VERSION ""

NS_ :

BS_:

BU_: Turbocharger OnBoardDataLogger OffBoardDiagnosticTool2 OffBoardDiagnosticTool1 FileServer ParkingBrakeController SeatControl2 FanDriveController SteeringColumnUnit CommunicationUnitRadio CommunicationUnitSatellite CommunicationUnitCellular PropulsionBatteryCharger ChassisController2 ChassisController1 EngineValveControl AuxiliaryHeater2 AuxiliaryHeater1 ClutchUnit RampControl InformationSystem1 SuspensionSystemController2 OilSensor VehicleDynamicStability ExhaustEmissionController TransmissionDisplay2 TransmissionDisplay1 ClimateControl2 WaterPumpController RearAxleSteeringController LightingOperatorControl SeatController1 IgnitionController2 IgnitionController1 TirePressureController CabController2 CabController1 PneumaticSystemController SuspensionSystemController1 HydraulicPumpController EnduranceBrakingSystem RetarderExhaustEngine2 OnBoardDiagnosticUnit HeadwayController RetarderExhaustEngine1 CabDisplay1 ManagementComputer VirtualTerminal OffVehicleGateway PowerTakeOffFront HitchControl AuxiliaryValveControl BodyController TractorTrailerBridge1 StarterSystem ElectricalSystem VehicleSecurity VehicleNavigation AerodynamicControl ElectricalChargingSystem ClimateControl1 TripRecorder InstrumentCluster SuspensionDriveAxle2 SuspensionDriveAxle1 SuspensionSteerAxle SteeringController FuelSystem CruiseControl RetarderDriveline RetarderEngine BrakesDriveAxle2 BrakesDriveAxle1 BrakesSystemController BrakesSteerAxle AxleDrive2 AxleDrive1 AxleSteering PowerTakeOff ShiftConsoleSecondary ShiftConsolePrimary Transmission2 Transmission1 Engine2 Engine1

BO_ 2566842366 VH: 8 Vector__XXX
 SG_ TotalPowerTakeoffHours : 32|32@1+ (0.05,0) [0|210554060.75] "hr" Vector__XXX
 SG_ TotalVehicleHours : 0|32@1+ (0.05,0) [0|210554060.75] "hr" Vector__XXX

BO_ 2566839550 IO: 8 Vector__XXX
 SG_ EngTotalIdleHours : 32|32@1+ (0.05,0) [0|210554060.75] "hr" Vector__XXX
 SG_ EngTotalIdleFuelUsed : 0|32@1+ (0.5,0) [0|2105540607.5] "L" Vector__XXX

BO_ 2566848510 WFI: 8 Vector__XXX
 SG_ WaterInFuelIndicator : 0|2@1+ (1,0) [0|3] "" Vector__XXX

BO_ 2566841854 HOURS: 8 Vector__XXX
 SG_ EngTotalRevolutions : 32|32@1+ (1000,0) [0|4211081215000] "r" Vector__XXX
 SG_ EngTotalHoursOfOperation : 0|32@1+ (0.05,0) [0|210554060.75] "hr" Vector__XXX

BO_ 2566842878 LFC: 8 Vector__XXX
 SG_ EngTotalFuelUsed : 32|32@1+ (0.5,0) [0|2105540607.5] "L" Vector__XXX
 SG_ EngTripFuel : 0|32@1+ (0.5,0) [0|2105540607.5] "L" Vector__XXX

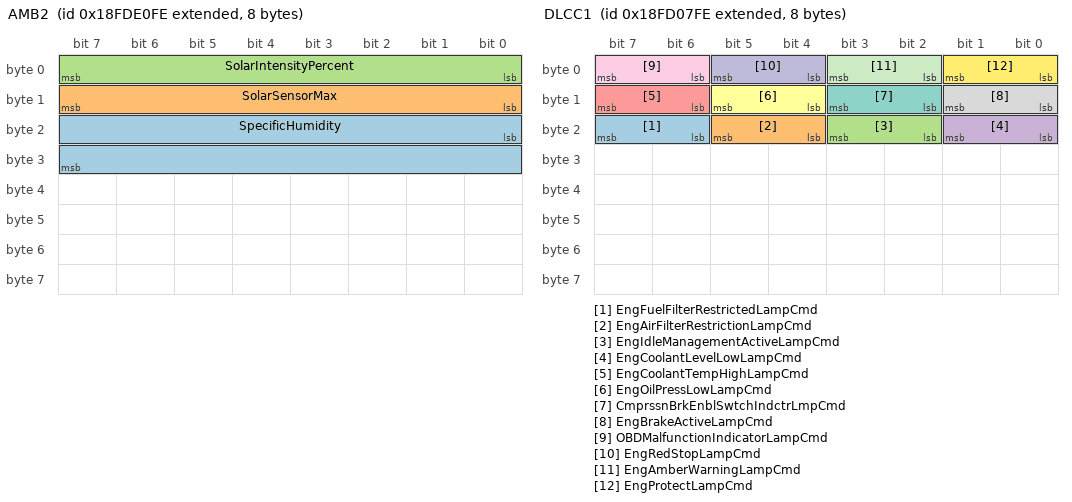
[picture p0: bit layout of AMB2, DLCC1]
BO_ 2566775038 AMB2: 8 Vector__XXX
 SG_ SpecificHumidity : 16|16@1+ (0.01,0) [0|642.55] "g/kg" Vector__XXX
 SG_ SolarSensorMax : 8|8@1+ (0.4,0) [0|100] "mW/cm/cm" Vector__XXX
 SG_ SolarIntensityPercent : 0|8@1+ (0.4,0) [0|100] "%" Vector__XXX

BO_ 2566834942 DM1: 22 Vector__XXX
 SG_ FlashRedStopLamp : 12|2@1+ (1,0) [0|3] "" Vector__XXX
 SG_ FlashProtectLamp : 8|2@1+ (1,0) [0|3] "" Vector__XXX
 SG_ FlashMalfuncIndicatorLamp : 14|2@1+ (1,0) [0|3] "" Vector__XXX
 SG_ FlashAmberWarningLamp : 10|2@1+ (1,0) [0|3] "" Vector__XXX
 SG_ MalfunctionIndicatorLampStatus : 6|2@1+ (1,0) [0|3] "" Vector__XXX
 SG_ AmberWarningLampStatus : 2|2@1+ (1,0) [0|3] "" Vector__XXX
 SG_ RedStopLampState : 4|2@1+ (1,0) [0|3] "" Vector__XXX
 SG_ ProtectLampStatus : 0|2@1+ (1,0) [0|3] "" Vector__XXX
 SG_ DTC5 : 144|32@1+ (1,0) [0|4294967295] "" Vector__XXX
 SG_ DTC4 : 112|32@1+ (1,0) [0|4294967295] "" Vector__XXX
 SG_ DTC3 : 80|32@1+ (1,0) [0|4294967295] "" Vector__XXX
 SG_ DTC2 : 48|32@1+ (1,0) [0|4294967295] "" Vector__XXX
 SG_ DTC1 : 16|32@1+ (1,0) [0|4294967295] "" Vector__XXX

BO_ 2566719486 DLCC1: 8 Vector__XXX
 SG_ EngFuelFilterRestrictedLampCmd : 22|2@1+ (1,0) [0|3] "" Vector__XXX
 SG_ EngAirFilterRestrictionLampCmd : 20|2@1+ (1,0) [0|3] "" Vector__XXX
 SG_ EngIdleManagementActiveLampCmd : 18|2@1+ (1,0) [0|3] "" Vector__XXX
 SG_ EngCoolantLevelLowLampCmd : 16|2@1+ (1,0) [0|3] "" Vector__XXX
 SG_ EngCoolantTempHighLampCmd : 14|2@1+ (1,0) [0|3] "" Vector__XXX
 SG_ EngOilPressLowLampCmd : 12|2@1+ (1,0) [0|3] "" Vector__XXX
 SG_ CmprssnBrkEnblSwtchIndctrLmpCmd : 10|2@1+ (1,0) [0|3] "" Vector__XXX
 SG_ EngBrakeActiveLampCmd : 8|2@1+ (1,0) [0|3] "" Vector__XXX
 SG_ OBDMalfunctionIndicatorLampCmd : 6|2@1+ (1,0) [0|3] "" Vector__XXX
 SG_ EngRedStopLampCmd : 4|2@1+ (1,0) [0|3] "" Vector__XXX
 SG_ EngAmberWarningLampCmd : 2|2@1+ (1,0) [0|3] "" Vector__XXX
 SG_ EngProtectLampCmd : 0|2@1+ (1,0) [0|3] "" Vector__XXX

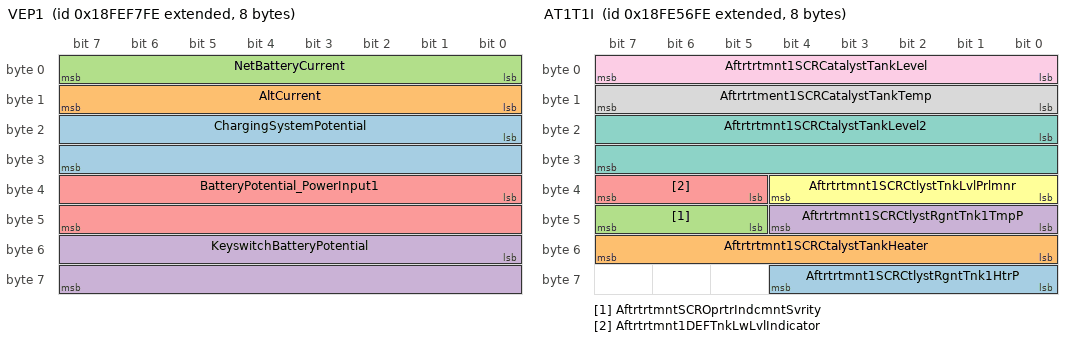
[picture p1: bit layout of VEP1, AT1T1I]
BO_ 2566846462 VEP1: 8 Vector__XXX
 SG_ ChargingSystemPotential : 16|16@1+ (0.05,0) [0|3212.75] "V" Vector__XXX
 SG_ AltCurrent : 8|8@1+ (1,0) [0|250] "A" Vector__XXX
 SG_ NetBatteryCurrent : 0|8@1+ (1,-125) [-125|125] "A" Vector__XXX
 SG_ KeyswitchBatteryPotential : 48|16@1+ (0.05,0) [0|3212.75] "V" Vector__XXX
 SG_ BatteryPotential_PowerInput1 : 32|16@1+ (0.05,0) [0|3212.75] "V" Vector__XXX

BO_ 2566832638 VDHR: 8 Vector__XXX
 SG_ HighResolutionTripDistance : 32|32@1+ (5,0) [0|21055406] "km" Vector__XXX
 SG_ HghRslutionTotalVehicleDistance : 0|32@1+ (5,0) [0|21055406] "km" Vector__XXX

BO_ 2566805246 AT1T1I: 8 Vector__XXX
 SG_ Aftrtrtmnt1SCRCtlystRgntTnk1HtrP : 56|5@1+ (1,0) [0|31] "" Vector__XXX
 SG_ Aftrtrtmnt1SCRCtalystTankHeater : 48|8@1+ (0.4,0) [0|100] "%" Vector__XXX
 SG_ AftrtrtmntSCROprtrIndcmntSvrity : 45|3@1+ (1,0) [0|7] "" Vector__XXX
 SG_ Aftrtrtmnt1SCRCtlystRgntTnk1TmpP : 40|5@1+ (1,0) [0|31] "" Vector__XXX
 SG_ Aftrtrtmnt1DEFTnkLwLvlIndicator : 37|3@1+ (1,0) [0|7] "" Vector__XXX
 SG_ Aftrtrtmnt1SCRCtlystTnkLvlPrlmnr : 32|5@1+ (1,0) [0|31] "" Vector__XXX
 SG_ Aftrtrtmnt1SCRCtalystTankLevel2 : 16|16@1+ (0.1,0) [0|6425.5] "mm" Vector__XXX
 SG_ Aftrtrtment1SCRCatalystTankTemp : 8|8@1+ (1,-40) [-40|210] "degC" Vector__XXX
 SG_ Aftrtrtmnt1SCRCatalystTankLevel : 0|8@1+ (0.4,0) [0|100] "%" Vector__XXX

BO_ 2566841598 SHUTDN: 8 Vector__XXX
 SG_ EngOverspeedTest : 54|2@1+ (1,0) [0|3] "" Vector__XXX
 SG_ EngAirShutoffCmdStatus : 52|2@1+ (1,0) [0|3] "" Vector__XXX
 SG_ EngAlarmOutputCmdStatus : 50|2@1+ (1,0) [0|3] "" Vector__XXX
 SG_ EngAlarmAcknowledge : 48|2@1+ (1,0) [0|3] "" Vector__XXX
 SG_ EngProtectionSystemConfig : 46|2@1+ (1,0) [0|3] "" Vector__XXX
 SG_ EngProtectionSystemTimerState : 38|2@1+ (1,0) [0|3] "" Vector__XXX
 SG_ EngPrtectionSystemTimerOverride : 36|2@1+ (1,0) [0|3] "" Vector__XXX
 SG_ EngPrtctnSystmApprchingShutdown : 34|2@1+ (1,0) [0|3] "" Vector__XXX
 SG_ EngWaitToStartLamp : 24|2@1+ (1,0) [0|3] "" Vector__XXX
 SG_ RefrigerantHighPressSwitch : 20|2@1+ (1,0) [0|3] "" Vector__XXX
 SG_ RefrigerantLowPressSwitch : 18|2@1+ (1,0) [0|3] "" Vector__XXX
 SG_ A_CHighPressFanSwitch : 16|2@1+ (1,0) [0|3] "" Vector__XXX
 SG_ EngIdleShutdownTimerFunction : 14|2@1+ (1,0) [0|3] "" Vector__XXX
 SG_ EngIdleShutdownTimerState : 6|2@1+ (1,0) [0|3] "" Vector__XXX
 SG_ EngIdleShutdownTimerOverride : 4|2@1+ (1,0) [0|3] "" Vector__XXX
 SG_ EngIdleShutdownDriverAlertMode : 2|2@1+ (1,0) [0|3] "" Vector__XXX
 SG_ PTOShutdownHasShutdownEng : 58|2@1+ (1,0) [0|3] "" Vector__XXX
 SG_ EngPrtctnSystmHasShutdownEngine : 32|2@1+ (1,0) [0|3] "" Vector__XXX
 SG_ EngIdlShutdownHasShutdownEngine : 0|2@1+ (1,0) [0|3] "" Vector__XXX
 SG_ EngAirShutoffStatus : 56|2@1+ (1,0) [0|3] "" Vector__XXX

BO_ 2566749438 DPFC1: 8 Vector__XXX
 SG_ DslPrtcltFltrActvRgnrtnFrcdStts : 53|3@1+ (1,0) [0|7] "" Vector__XXX
 SG_ ExhaustSystemHighTempLampCmd : 50|3@1+ (1,0) [0|7] "" Vector__XXX
 SG_ DslPrtcltFltrAtmtcActvRgnrtnIntt : 48|2@1+ (1,0) [0|3] "" Vector__XXX
 SG_ DslPrtcltFltrActvRgnrtnInhbtdDTV : 46|2@1+ (1,0) [0|3] "" Vector__XXX
 SG_ DslPrtcltFltrActvRgnrtnInhbtdDTE : 44|2@1+ (1,0) [0|3] "" Vector__XXX
 SG_ DslPrtcltFltrActvRgnrtnInhbtdDTP : 42|2@1+ (1,0) [0|3] "" Vector__XXX
 SG_ DslPrtcltFltrActvRgnrtnInhbtdDTT : 40|2@1+ (1,0) [0|3] "" Vector__XXX
 SG_ DslPrtcltFltrActvRgnrtnInhbtdDTS : 38|2@1+ (1,0) [0|3] "" Vector__XXX
 SG_ DslPrtcltFltrActvRgnrtnInhb_0000 : 36|2@1+ (1,0) [0|3] "" Vector__XXX
 SG_ DslPrtcltFltrActvRgnrtnInhbtdDTL : 34|2@1+ (1,0) [0|3] "" Vector__XXX
 SG_ DslPrtcltFltrActvRgnrtnInhb_0001 : 32|2@1+ (1,0) [0|3] "" Vector__XXX
 SG_ DslPrtcltFltrActvRgnrtnInhb_0002 : 30|2@1+ (1,0) [0|3] "" Vector__XXX
 SG_ DslPrtcltFltrActvRgnrtnInhbtdDTO : 28|2@1+ (1,0) [0|3] "" Vector__XXX
 SG_ DslPrtcltFltrActvRgnrtnInhbtdDTA : 26|2@1+ (1,0) [0|3] "" Vector__XXX
 SG_ DslPrtcltFltrActvRgnrtnInhb_0003 : 24|2@1+ (1,0) [0|3] "" Vector__XXX
 SG_ DslPrtcltFltrActvRgnrtnInhb_0004 : 22|2@1+ (1,0) [0|3] "" Vector__XXX
 SG_ DslPrtcltFltrActvRgnrtnInhbtdDTC : 20|2@1+ (1,0) [0|3] "" Vector__XXX
 SG_ DslPrtcltFltrActvRgnrtnInhbtdDTI : 18|2@1+ (1,0) [0|3] "" Vector__XXX
 SG_ DslPrtcltFltrActvRgnrtnInhbtdStt : 16|2@1+ (1,0) [0|3] "" Vector__XXX
 SG_ DieselParticulateFilterStatus : 12|3@1+ (1,0) [0|7] "" Vector__XXX
 SG_ DslPrtcltFltrActvRgnrtionStatus : 10|2@1+ (1,0) [0|3] "" Vector__XXX
 SG_ DslPrtcltFltrPssvRgnrtionStatus : 8|2@1+ (1,0) [0|3] "" Vector__XXX
 SG_ DieselParticulateFilterLampCmd : 0|3@1+ (1,0) [0|7] "" Vector__XXX

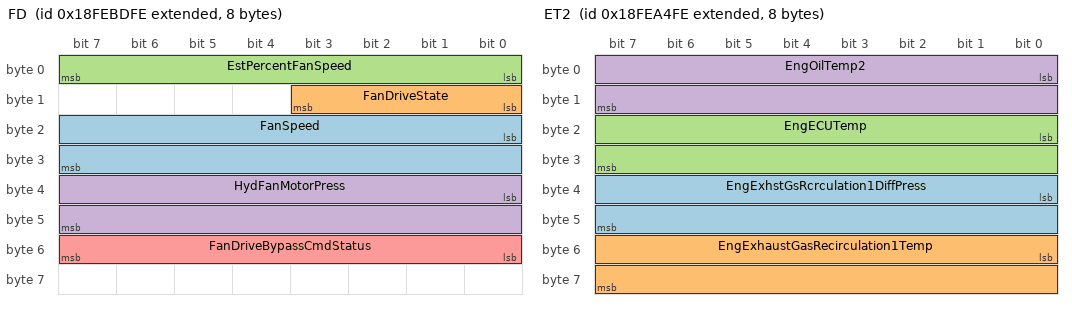
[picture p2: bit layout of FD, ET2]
BO_ 2566831614 FD: 8 Vector__XXX
 SG_ FanSpeed : 16|16@1+ (0.125,0) [0|8031.875] "rpm" Vector__XXX
 SG_ FanDriveState : 8|4@1+ (1,0) [0|15] "" Vector__XXX
 SG_ EstPercentFanSpeed : 0|8@1+ (0.4,0) [0|100] "%" Vector__XXX
 SG_ HydFanMotorPress : 32|16@1+ (0.5,0) [0|32127.5] "kPa" Vector__XXX
 SG_ FanDriveBypassCmdStatus : 48|8@1+ (0.4,0) [0|100] "%" Vector__XXX

BO_ 2566825214 ET2: 8 Vector__XXX
 SG_ EngExhstGsRcrculation1DiffPress : 32|16@1+ (0.0078125,-250) [-250|251.99] "kPa" Vector__XXX
 SG_ EngExhaustGasRecirculation1Temp : 48|16@1+ (0.03125,-273) [-273|1734.96875] "degC" Vector__XXX
 SG_ EngECUTemp : 16|16@1+ (0.03125,-273) [-273|1734.96875] "degC" Vector__XXX
 SG_ EngOilTemp2 : 0|16@1+ (0.03125,-273) [-273|1734.96875] "degC" Vector__XXX

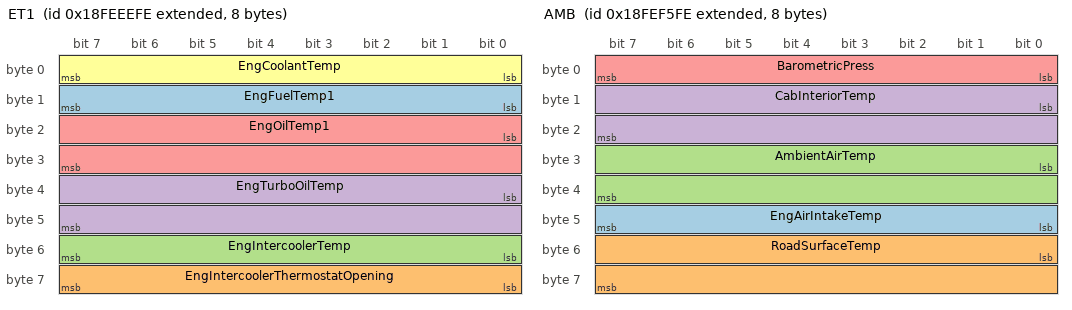
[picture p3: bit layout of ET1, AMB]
BO_ 2566844158 ET1: 8 Vector__XXX
 SG_ EngFuelTemp1 : 8|8@1+ (1,-40) [-40|210] "degC" Vector__XXX
 SG_ EngIntercoolerThermostatOpening : 56|8@1+ (0.4,0) [0|100] "%" Vector__XXX
 SG_ EngIntercoolerTemp : 48|8@1+ (1,-40) [-40|210] "degC" Vector__XXX
 SG_ EngTurboOilTemp : 32|16@1+ (0.03125,-273) [-273|1734.96875] "degC" Vector__XXX
 SG_ EngOilTemp1 : 16|16@1+ (0.03125,-273) [-273|1734.96875] "degC" Vector__XXX
 SG_ EngCoolantTemp : 0|8@1+ (0.03125,-273) [-273|-265.03125] "degC" Vector__XXX

BO_ 2566845950 AMB: 8 Vector__XXX
 SG_ EngAirIntakeTemp : 40|8@1+ (1,-40) [-40|210] "degC" Vector__XXX
 SG_ RoadSurfaceTemp : 48|16@1+ (0.03125,-273) [-273|1734.96875] "degC" Vector__XXX
 SG_ AmbientAirTemp : 24|16@1+ (0.03125,-273) [-273|1734.96875] "degC" Vector__XXX
 SG_ CabInteriorTemp : 8|16@1+ (0.03125,-273) [-273|1734.96875] "degC" Vector__XXX
 SG_ BarometricPress : 0|8@1+ (0.5,0) [0|125] "kPa" Vector__XXX

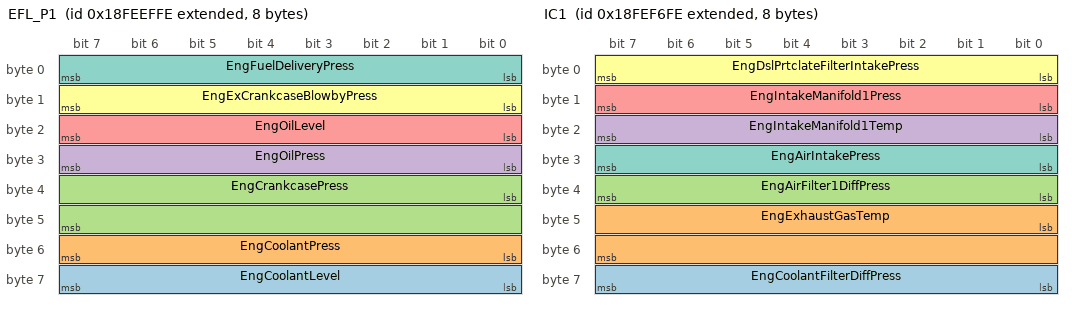
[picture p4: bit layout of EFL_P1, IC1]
BO_ 2566844414 EFL_P1: 8 Vector__XXX
 SG_ EngCoolantLevel : 56|8@1+ (0.4,0) [0|100] "%" Vector__XXX
 SG_ EngCoolantPress : 48|8@1+ (2,0) [0|500] "kPa" Vector__XXX
 SG_ EngCrankcasePress : 32|16@1+ (0.0078125,-250) [-250|251.99] "kPa" Vector__XXX
 SG_ EngOilPress : 24|8@1+ (4,0) [0|1000] "kPa" Vector__XXX
 SG_ EngOilLevel : 16|8@1+ (0.4,0) [0|100] "%" Vector__XXX
 SG_ EngExCrankcaseBlowbyPress : 8|8@1+ (0.05,0) [0|12.5] "kPa" Vector__XXX
 SG_ EngFuelDeliveryPress : 0|8@1+ (4,0) [0|1000] "kPa" Vector__XXX

BO_ 2566846206 IC1: 8 Vector__XXX
 SG_ EngCoolantFilterDiffPress : 56|8@1+ (0.5,0) [0|125] "kPa" Vector__XXX
 SG_ EngExhaustGasTemp : 40|16@1+ (0.03125,-273) [-273|1734.96875] "degC" Vector__XXX
 SG_ EngAirFilter1DiffPress : 32|8@1+ (0.05,0) [0|12.5] "kPa" Vector__XXX
 SG_ EngIntakeManifold1Temp : 16|8@1+ (1,-40) [-40|210] "degC" Vector__XXX
 SG_ EngIntakeManifold1Press : 8|8@1+ (2,0) [0|500] "kPa" Vector__XXX
 SG_ EngDslPrtclateFilterIntakePress : 0|8@1+ (0.5,0) [0|125] "kPa" Vector__XXX
 SG_ EngAirIntakePress : 24|8@1+ (2,0) [0|500] "kPa" Vector__XXX

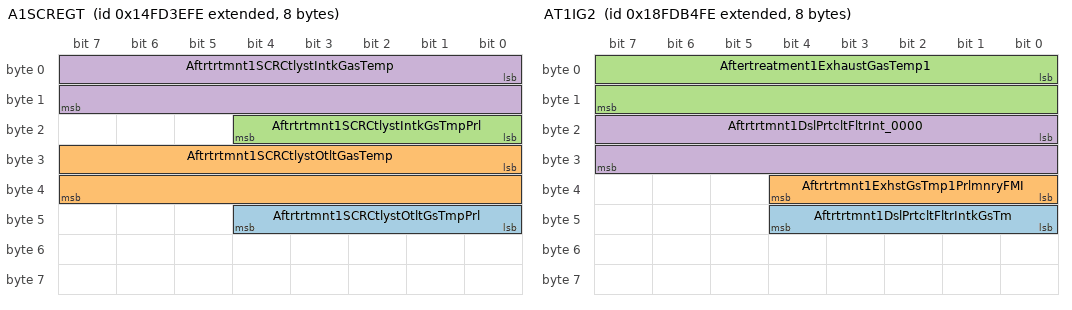
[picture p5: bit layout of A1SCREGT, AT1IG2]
BO_ 2499624702 A1SCREGT: 8 Vector__XXX
 SG_ Aftrtrtmnt1SCRCtlystOtltGsTmpPrl : 40|5@1+ (1,0) [0|31] "" Vector__XXX
 SG_ Aftrtrtmnt1SCRCtlystOtltGasTemp : 24|16@1+ (0.03125,-273) [-273|1734.96875] "degC" Vector__XXX
 SG_ Aftrtrtmnt1SCRCtlystIntkGsTmpPrl : 16|5@1+ (1,0) [0|31] "" Vector__XXX
 SG_ Aftrtrtmnt1SCRCtlystIntkGasTemp : 0|16@1+ (0.03125,-273) [-273|1734.96875] "degC" Vector__XXX

BO_ 2566844926 CCVS: 8 Vector__XXX
 SG_ ParkBrakeReleaseInhibitRq : 6|2@1+ (1,0) [0|3] "" Vector__XXX
 SG_ PTOGovernorState : 48|5@1+ (1,0) [0|31] "" Vector__XXX
 SG_ EngShutdownOverrideSwitch : 62|2@1+ (1,0) [0|3] "" Vector__XXX
 SG_ EngTestModeSwitch : 60|2@1+ (1,0) [0|3] "" Vector__XXX
 SG_ EngIdleDecrementSwitch : 58|2@1+ (1,0) [0|3] "" Vector__XXX
 SG_ EngIdleIncrementSwitch : 56|2@1+ (1,0) [0|3] "" Vector__XXX
 SG_ CruiseCtrlStates : 53|3@1+ (1,0) [0|7] "" Vector__XXX
 SG_ CruiseCtrlSetSpeed : 40|8@1+ (1,0) [0|250] "km/h" Vector__XXX
 SG_ CruiseCtrlAccelerateSwitch : 38|2@1+ (1,0) [0|3] "" Vector__XXX
 SG_ CruiseCtrlResumeSwitch : 36|2@1+ (1,0) [0|3] "" Vector__XXX
 SG_ CruiseCtrlCoastSwitch : 34|2@1+ (1,0) [0|3] "" Vector__XXX
 SG_ CruiseCtrlSetSwitch : 32|2@1+ (1,0) [0|3] "" Vector__XXX
 SG_ ClutchSwitch : 30|2@1+ (1,0) [0|3] "" Vector__XXX
 SG_ BrakeSwitch : 28|2@1+ (1,0) [0|3] "" Vector__XXX
 SG_ CruiseCtrlEnableSwitch : 26|2@1+ (1,0) [0|3] "" Vector__XXX
 SG_ CruiseCtrlActive : 24|2@1+ (1,0) [0|3] "" Vector__XXX
 SG_ WheelBasedVehicleSpeed : 8|16@1+ (0.00390625,0) [0|250.996] "km/h" Vector__XXX
 SG_ CruiseCtrlPauseSwitch : 4|2@1+ (1,0) [0|3] "" Vector__XXX
 SG_ ParkingBrakeSwitch : 2|2@1+ (1,0) [0|3] "" Vector__XXX
 SG_ TwoSpeedAxleSwitch : 0|2@1+ (1,0) [0|3] "" Vector__XXX

BO_ 2566763774 AT1IG2: 8 Vector__XXX
 SG_ Aftrtrtmnt1DslPrtcltFltrIntkGsTm : 40|5@1+ (1,0) [0|31] "" Vector__XXX
 SG_ Aftrtrtmnt1ExhstGsTmp1PrlmnryFMI : 32|5@1+ (1,0) [0|31] "" Vector__XXX
 SG_ Aftertreatment1ExhaustGasTemp1 : 0|16@1+ (0.03125,-273) [-273|1734.96875] "degC" Vector__XXX
 SG_ Aftrtrtmnt1DslPrtcltFltrInt_0000 : 16|16@1+ (0.03125,-273) [-273|1734.96875] "degC" Vector__XXX

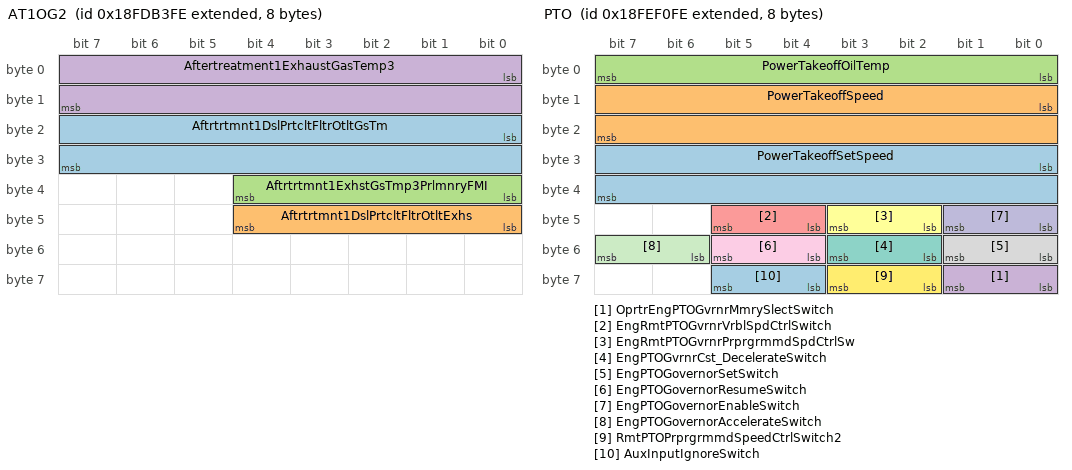
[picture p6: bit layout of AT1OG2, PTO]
BO_ 2566763518 AT1OG2: 8 Vector__XXX
 SG_ Aftrtrtmnt1DslPrtcltFltrOtltGsTm : 16|16@1+ (0.03125,-273) [-273|1734.96875] "degC" Vector__XXX
 SG_ Aftrtrtmnt1DslPrtcltFltrOtltExhs : 40|5@1+ (1,0) [0|31] "" Vector__XXX
 SG_ Aftrtrtmnt1ExhstGsTmp3PrlmnryFMI : 32|5@1+ (1,0) [0|31] "" Vector__XXX
 SG_ Aftertreatment1ExhaustGasTemp3 : 0|16@1+ (0.03125,-273) [-273|1734.96875] "degC" Vector__XXX

BO_ 2566840574 VD: 8 Vector__XXX
 SG_ TotalVehicleDistance : 32|32@1+ (0.125,0) [0|526385151.9] "km" Vector__XXX
 SG_ TripDistance : 0|32@1+ (0.125,0) [0|526385151.9] "km" Vector__XXX

BO_ 2566844670 PTO: 8 Vector__XXX
 SG_ PowerTakeoffSetSpeed : 24|16@1+ (0.125,0) [0|8031.875] "rpm" Vector__XXX
 SG_ PowerTakeoffSpeed : 8|16@1+ (0.125,0) [0|8031.875] "rpm" Vector__XXX
 SG_ PowerTakeoffOilTemp : 0|8@1+ (1,-40) [-40|210] "degC" Vector__XXX
 SG_ OprtrEngPTOGvrnrMmrySlectSwitch : 56|2@1+ (1,0) [0|3] "" Vector__XXX
 SG_ EngRmtPTOGvrnrVrblSpdCtrlSwitch : 44|2@1+ (1,0) [0|3] "" Vector__XXX
 SG_ EngRmtPTOGvrnrPrprgrmmdSpdCtrlSw : 42|2@1+ (1,0) [0|3] "" Vector__XXX
 SG_ EngPTOGvrnrCst_DecelerateSwitch : 50|2@1+ (1,0) [0|3] "" Vector__XXX
 SG_ EngPTOGovernorSetSwitch : 48|2@1+ (1,0) [0|3] "" Vector__XXX
 SG_ EngPTOGovernorResumeSwitch : 52|2@1+ (1,0) [0|3] "" Vector__XXX
 SG_ EngPTOGovernorEnableSwitch : 40|2@1+ (1,0) [0|3] "" Vector__XXX
 SG_ EngPTOGovernorAccelerateSwitch : 54|2@1+ (1,0) [0|3] "" Vector__XXX
 SG_ RmtPTOPrprgrmmdSpeedCtrlSwitch2 : 58|2@1+ (1,0) [0|3] "" Vector__XXX
 SG_ AuxInputIgnoreSwitch : 60|2@1+ (1,0) [0|3] "" Vector__XXX

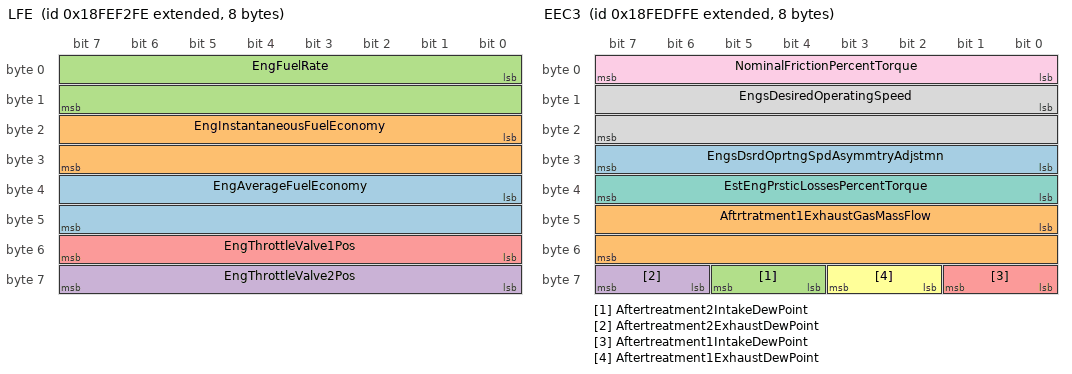
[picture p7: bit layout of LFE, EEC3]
BO_ 2566845182 LFE: 8 Vector__XXX
 SG_ EngAverageFuelEconomy : 32|16@1+ (0.001953125,0) [0|125.5] "km/L" Vector__XXX
 SG_ EngInstantaneousFuelEconomy : 16|16@1+ (0.001953125,0) [0|125.5] "km/L" Vector__XXX
 SG_ EngFuelRate : 0|16@1+ (0.05,0) [0|3212.75] "L/h" Vector__XXX
 SG_ EngThrottleValve2Pos : 56|8@1+ (0.4,0) [0|100] "%" Vector__XXX
 SG_ EngThrottleValve1Pos : 48|8@1+ (0.4,0) [0|100] "%" Vector__XXX

BO_ 2566840318 EEC3: 8 Vector__XXX
 SG_ EngsDsrdOprtngSpdAsymmtryAdjstmn : 24|8@1+ (1,0) [0|250] "" Vector__XXX
 SG_ Aftrtratment1ExhaustGasMassFlow : 40|16@1+ (0.2,0) [0|12851] "kg/h" Vector__XXX
 SG_ Aftertreatment2IntakeDewPoint : 60|2@1+ (1,0) [0|3] "" Vector__XXX
 SG_ Aftertreatment2ExhaustDewPoint : 62|2@1+ (1,0) [0|3] "" Vector__XXX
 SG_ Aftertreatment1IntakeDewPoint : 56|2@1+ (1,0) [0|3] "" Vector__XXX
 SG_ Aftertreatment1ExhaustDewPoint : 58|2@1+ (1,0) [0|3] "" Vector__XXX
 SG_ EstEngPrsticLossesPercentTorque : 32|8@1+ (1,-125) [-125|125] "%" Vector__XXX
 SG_ EngsDesiredOperatingSpeed : 8|16@1+ (0.125,0) [0|8031.875] "rpm" Vector__XXX
 SG_ NominalFrictionPercentTorque : 0|8@1+ (1,-125) [-125|125] "%" Vector__XXX

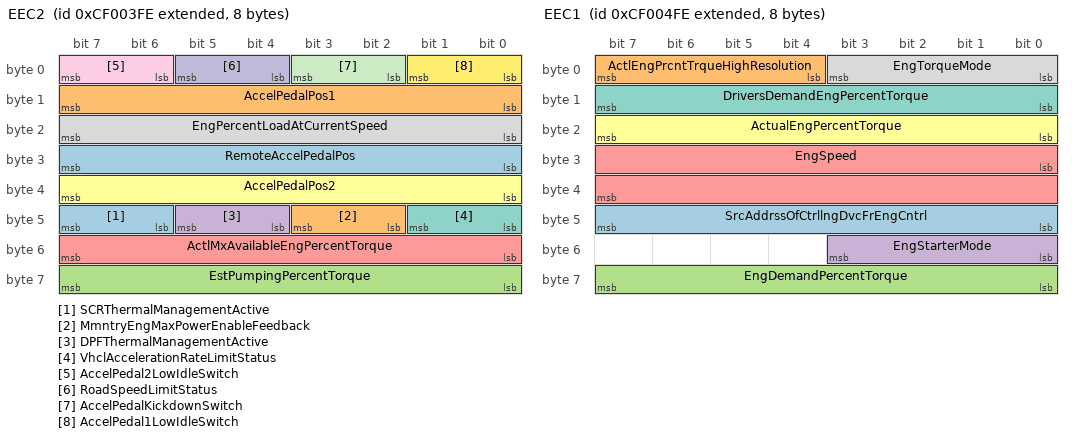
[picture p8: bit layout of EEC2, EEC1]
BO_ 2364539902 EEC2: 8 Vector__XXX
 SG_ SCRThermalManagementActive : 46|2@1+ (1,0) [0|3] "" Vector__XXX
 SG_ MmntryEngMaxPowerEnableFeedback : 42|2@1+ (1,0) [0|3] "" Vector__XXX
 SG_ EstPumpingPercentTorque : 56|8@1+ (1,-125) [-125|125] "%" Vector__XXX
 SG_ DPFThermalManagementActive : 44|2@1+ (1,0) [0|3] "" Vector__XXX
 SG_ ActlMxAvailableEngPercentTorque : 48|8@1+ (0.4,0) [0|100] "%" Vector__XXX
 SG_ AccelPedalPos2 : 32|8@1+ (0.4,0) [0|100] "%" Vector__XXX
 SG_ VhclAccelerationRateLimitStatus : 40|2@1+ (1,0) [0|3] "" Vector__XXX
 SG_ EngPercentLoadAtCurrentSpeed : 16|8@1+ (1,0) [0|250] "%" Vector__XXX
 SG_ AccelPedal2LowIdleSwitch : 6|2@1+ (1,0) [0|3] "" Vector__XXX
 SG_ RoadSpeedLimitStatus : 4|2@1+ (1,0) [0|3] "" Vector__XXX
 SG_ AccelPedalKickdownSwitch : 2|2@1+ (1,0) [0|3] "" Vector__XXX
 SG_ AccelPedal1LowIdleSwitch : 0|2@1+ (1,0) [0|3] "" Vector__XXX
 SG_ RemoteAccelPedalPos : 24|8@1+ (0.4,0) [0|100] "%" Vector__XXX
 SG_ AccelPedalPos1 : 8|8@1+ (0.4,0) [0|100] "%" Vector__XXX

BO_ 2364540158 EEC1: 8 Vector__XXX
 SG_ SrcAddrssOfCtrllngDvcFrEngCntrl : 40|8@1+ (1,0) [0|255] "" Vector__XXX
 SG_ ActlEngPrcntTrqueHighResolution : 4|4@1+ (0.125,0) [0|0.875] "%" Vector__XXX
 SG_ EngDemandPercentTorque : 56|8@1+ (1,-125) [-125|125] "%" Vector__XXX
 SG_ EngStarterMode : 48|4@1+ (1,0) [0|15] "" Vector__XXX
 SG_ EngSpeed : 24|16@1+ (0.125,0) [0|8031.875] "rpm" Vector__XXX
 SG_ ActualEngPercentTorque : 16|8@1+ (1,-125) [-125|125] "%" Vector__XXX
 SG_ DriversDemandEngPercentTorque : 8|8@1+ (1,-125) [-125|125] "%" Vector__XXX
 SG_ EngTorqueMode : 0|4@1+ (1,0) [0|15] "" Vector__XXX

CM_ BO_ 2566842366 "Vehicle Hours";
CM_ SG_ 2566842366 TotalPowerTakeoffHours "Accumulated time of operation of power takeoff device.";
CM_ SG_ 2566842366 TotalVehicleHours "Accumulated time of operation of vehicle.";
CM_ BO_ 2566839550 "Idle Operation";
CM_ SG_ 2566839550 EngTotalIdleHours "Accumulated time of operation of the engine while under idle conditions.";
CM_ SG_ 2566839550 EngTotalIdleFuelUsed "Accumulated amount of fuel used during vehicle operation while under idle conditions.";
CM_ BO_ 2566848510 "Water in Fuel Indicator";
CM_ SG_ 2566848510 WaterInFuelIndicator "Signal which indicates the presence of water in the fuel.";
CM_ BO_ 2566841854 "Engine Hours, Revolutions";
CM_ SG_ 2566841854 EngTotalRevolutions "Accumulated number of revolutions of engine crankshaft during its operation.";
CM_ SG_ 2566841854 EngTotalHoursOfOperation "Accumulated time of operation of engine.";
CM_ BO_ 2566842878 "Fuel Consumption (Liquid)";
CM_ SG_ 2566842878 EngTotalFuelUsed "Accumulated amount of fuel used during vehicle operation.";
CM_ SG_ 2566842878 EngTripFuel "Fuel consumed during all or part of a journey.";
CM_ BO_ 2566775038 "Ambient Conditions 2";
CM_ SG_ 2566775038 SpecificHumidity "Specific humidity of the ambient intake air.";
CM_ SG_ 2566775038 SolarSensorMax "This is the maximum value which can be reported by the sensor for the solar intensity.";
CM_ SG_ 2566775038 SolarIntensityPercent "This is the solar radiation (power density) falling on the vehicle in percent of the maximum sensor value (SPN 2611).";
CM_ BO_ 2566834942 "Active diagnostic trouble codes";
CM_ SG_ 2566834942 FlashRedStopLamp "This parameter provides the capability to flash the RSL (SPN 3039).";
CM_ SG_ 2566834942 FlashProtectLamp "This parameter provides the capability to flash the engine protect lamp (SPN 3041).";
CM_ SG_ 2566834942 FlashMalfuncIndicatorLamp "This parameter provides the capability to flash the MIL (SPN 3038).";
CM_ SG_ 2566834942 FlashAmberWarningLamp "This parameter provides the capability to flash the AWL (SPN 3040). ";
CM_ SG_ 2566834942 MalfunctionIndicatorLampStatus "A lamp used to relay only emissions-related trouble code information.";
CM_ SG_ 2566834942 AmberWarningLampStatus "This lamp is used to relay trouble code information that is reporting a problem with the vehicle system but the vehicle need
not be immediately stopped.";
CM_ SG_ 2566834942 RedStopLampState "This lamp is uesed to relay trouble code information that is of a severe enought condition that it warrants stopping the vehicle.";
CM_ SG_ 2566834942 ProtectLampStatus "This lamp is used to relay trouble code informatio that is reporting a problem with a vehicle system that is most
probably not electronic subsystem related.";
CM_ SG_ 2566834942 DTC5 "Diagnostic Trouble Code";
CM_ SG_ 2566834942 DTC4 "Diagnostic Trouble Code";
CM_ SG_ 2566834942 DTC3 "Diagnostic Trouble Code";
CM_ SG_ 2566834942 DTC2 "Diagnostic Trouble Code";
CM_ SG_ 2566834942 DTC1 "Diagnostic Trouble Code";
CM_ BO_ 2566719486 "Direct Lamp Control Command 1";
CM_ SG_ 2566719486 EngFuelFilterRestrictedLampCmd "Command signal directly controlling the Vehicle Fuel Filter Restricted Lamp.";
CM_ SG_ 2566719486 EngAirFilterRestrictionLampCmd "Command signal directly controlling the Engine Air Filter Restriction Lamp.";
CM_ SG_ 2566719486 EngIdleManagementActiveLampCmd "Command signal directly controlling the Engine Idle Management Active Lamp";
CM_ SG_ 2566719486 EngCoolantLevelLowLampCmd "Command signal directly controlling the Engine Coolant Level Low Lamp";
CM_ SG_ 2566719486 EngCoolantTempHighLampCmd "Command signal directly controlling the Engine Coolant Temperature High Lamp";
CM_ SG_ 2566719486 EngOilPressLowLampCmd "Command signal directly controlling the Engine Oil Pressure Low Lamp";
CM_ SG_ 2566719486 CmprssnBrkEnblSwtchIndctrLmpCmd "Command signal directly controlling Compression Brake Enable Switch Indicator Lamp.";
CM_ SG_ 2566719486 EngBrakeActiveLampCmd "Command signal directly controlling the Engine Brake Active Lamp";
CM_ SG_ 2566719486 OBDMalfunctionIndicatorLampCmd "Command signal directly controlling the OBD Malfunction Indicator Lamp";
CM_ SG_ 2566719486 EngRedStopLampCmd "Command signal directly controlling the Engine Red Stop Lamp";
CM_ SG_ 2566719486 EngAmberWarningLampCmd "Command signal directly controlling the Engine Amber Warning Lamp";
CM_ SG_ 2566719486 EngProtectLampCmd "Command signal directly controlling the Engine Protect Lamp";
CM_ BO_ 2566846462 "Vehicle Electrical Power 1";
CM_ SG_ 2566846462 ChargingSystemPotential "Electrical potential measured at the charging system output.";
CM_ SG_ 2566846462 AltCurrent "Measure of electrical current flow from the alternator.";
CM_ SG_ 2566846462 NetBatteryCurrent "Net flow of electrical current into/out of the battery or batteries.";
CM_ SG_ 2566846462 KeyswitchBatteryPotential "Battery potential measured at the input of the electronic control unit supplied through a keyswitch or similar switching";
CM_ SG_ 2566846462 BatteryPotential_PowerInput1 "This parameter measures the first source of battery potential as measured at the input of the ECM/actuator etc.";
CM_ BO_ 2566832638 "High Resolution Vehicle Distance";
CM_ SG_ 2566832638 HighResolutionTripDistance "Distance traveled during all or part of a journey.";
CM_ SG_ 2566832638 HghRslutionTotalVehicleDistance "Accumulated distance traveled by the vehicle during its operation.";
CM_ BO_ 2566805246 "Aftertreatment 1 SCR Reagent Tank 1 Information";
CM_ SG_ 2566805246 Aftrtrtmnt1SCRCtlystRgntTnk1HtrP "Used to identify the applicable J1939-73 FMI detected in the SCR catalyst reagent tank 1 heater, by the manufacturer's";
CM_ SG_ 2566805246 Aftrtrtmnt1SCRCtalystTankHeater "Percentage of heating applied to the aftertreatment 1 catalyst tank heater.";
CM_ SG_ 2566805246 AftrtrtmntSCROprtrIndcmntSvrity "The severity of operator inducement for anomolies with the SCR system, such as tampering, low DEF quality, and DEF";
CM_ SG_ 2566805246 Aftrtrtmnt1SCRCtlystRgntTnk1TmpP "Used to identify the applicable J1939-73 FMI detected in the SCR catalyst reagent tank 1 temperature, by the";
CM_ SG_ 2566805246 Aftrtrtmnt1DEFTnkLwLvlIndicator "The desired illumination of the driver's warning indicator for diesel exhaust fluid (DEF) tank low level.";
CM_ SG_ 2566805246 Aftrtrtmnt1SCRCtlystTnkLvlPrlmnr "Used to identify the applicable J1939-73 FMI that applies to the most significant failure of the catalyst tank level sensor.";
CM_ SG_ 2566805246 Aftrtrtmnt1SCRCtalystTankLevel2 "The measure of the reagent level in the catalyst tank.";
CM_ SG_ 2566805246 Aftrtrtment1SCRCatalystTankTemp "Temperature of the reagent in the storage tank.";
CM_ SG_ 2566805246 Aftrtrtmnt1SCRCatalystTankLevel "A special catalyst uses a chemical reagent to reach legal requirement for NOX emissions.";
CM_ BO_ 2566841598 "Shutdown";
CM_ SG_ 2566841598 EngOverspeedTest "The engine overspeed test signal as measured by the reporting ECM.";
CM_ SG_ 2566841598 EngAirShutoffCmdStatus "State signal which indicates when the Air Shutoff driver output is being driven.";
CM_ SG_ 2566841598 EngAlarmOutputCmdStatus "State signal which indicates when the Alarm driver output is being driven.";
CM_ SG_ 2566841598 EngAlarmAcknowledge "The Engine Alarm Acknowledge Input signal as measured by the reporting ECM.";
CM_ SG_ 2566841598 EngProtectionSystemConfig "Parameter which indicates the configuration of the engine shutdown system.";
CM_ SG_ 2566841598 EngProtectionSystemTimerState "Status signal which indicates the current mode of the engine protection system timer system.";
CM_ SG_ 2566841598 EngPrtectionSystemTimerOverride "Status signal which indicates the status of the override feature of the engine protection system timer.";
CM_ SG_ 2566841598 EngPrtctnSystmApprchingShutdown "Status signal which indicates that engine shutdown is imminent.";
CM_ SG_ 2566841598 EngWaitToStartLamp "Lamp signal which indicates that the engine is too cold to start and the operator should wait until the signal becomes";
CM_ SG_ 2566841598 RefrigerantHighPressSwitch "Switch signal which indicates the position of the high pressure switch in the coolant circuit of an air conditioning system.";
CM_ SG_ 2566841598 RefrigerantLowPressSwitch "Switch signal which indicates the position of the low pressure switch in the coolant circuit of an air conditioning system.";
CM_ SG_ 2566841598 A_CHighPressFanSwitch "Switch signal which indicates that the pressure in the coolant circuit of an air conditioning system is high and the fan may";
CM_ SG_ 2566841598 EngIdleShutdownTimerFunction "Parameter which indicates the configuration of the idle shutdown timer system.";
CM_ SG_ 2566841598 EngIdleShutdownTimerState "Status signal which indicates the current mode of operation of the idle shutdown timer system.";
CM_ SG_ 2566841598 EngIdleShutdownTimerOverride "Status signal which indicates the status of the override feature of the idle shutdown timer system.";
CM_ SG_ 2566841598 EngIdleShutdownDriverAlertMode "Status signal which indicates the status of the driver alert mode of the idle shutdown timer system.";
CM_ SG_ 2566841598 PTOShutdownHasShutdownEng "Status signal which identifies whether or not the engine has been shutdown by the PTO shutdown system.";
CM_ SG_ 2566841598 EngPrtctnSystmHasShutdownEngine "Status signal which indicates whether or not the engine protection system has shutdown the engine.";
CM_ SG_ 2566841598 EngIdlShutdownHasShutdownEngine "Status signal which identifies whether or not the engine has been shutdown by the idle shutdown timer system.";
CM_ SG_ 2566841598 EngAirShutoffStatus "State signal which indicates the actual measured position of the Air Shutoff.";
CM_ BO_ 2566749438 "Diesel Particulate Filter Control 1";
CM_ SG_ 2566749438 DslPrtcltFltrActvRgnrtnFrcdStts "Indicates the forced execution status of diesel particulate filter regeneration.";
CM_ SG_ 2566749438 ExhaustSystemHighTempLampCmd "Command to control the exhaust system high temperature lamp.";
CM_ SG_ 2566749438 DslPrtcltFltrAtmtcActvRgnrtnIntt "Indicates the configuration of diesel particulate filter active regeneration automatic initiation.";
CM_ SG_ 2566749438 DslPrtcltFltrActvRgnrtnInhbtdDTV "Speed";
CM_ SG_ 2566749438 DslPrtcltFltrActvRgnrtnInhbtdDTE "Indicates the state of diesel particulate filter active regeneration inhibition due to the engine not being warmed up.";
CM_ SG_ 2566749438 DslPrtcltFltrActvRgnrtnInhbtdDTP "Indicates the state of diesel particulate filter active regeneration inhibition due to a permanent system lockout.";
CM_ SG_ 2566749438 DslPrtcltFltrActvRgnrtnInhbtdDTT "Indicates the state of diesel particulate filter active regeneration inhibition due to a temporary system lockout.";
CM_ SG_ 2566749438 DslPrtcltFltrActvRgnrtnInhbtdDTS "Indicates the state of diesel particulate filter active regeneration inhibition due to a system timeout.";
CM_ SG_ 2566749438 DslPrtcltFltrActvRgnrtnInhb_0000 "Indicates the state of diesel particulate filter active regeneration inhibition due to a system fault being active.";
CM_ SG_ 2566749438 DslPrtcltFltrActvRgnrtnInhbtdDTL "Indicates the state of diesel particulate filter active regeneration inhibition due to the exhaust gas temperature being too";
CM_ SG_ 2566749438 DslPrtcltFltrActvRgnrtnInhb_0001 "Indicates the state of diesel particulate filter active regeneration inhibition due to the parking brake being not set.";
CM_ SG_ 2566749438 DslPrtcltFltrActvRgnrtnInhb_0002 "Speed";
CM_ SG_ 2566749438 DslPrtcltFltrActvRgnrtnInhbtdDTO "Indicates the state of diesel particulate filter active regeneration inhibition due to the transmission being out of neutral.";
CM_ SG_ 2566749438 DslPrtcltFltrActvRgnrtnInhbtdDTA "Indicates the state of diesel particulate filter active regeneration inhibition due to the accelerator pedal being off idle.";
CM_ SG_ 2566749438 DslPrtcltFltrActvRgnrtnInhb_0003 "Indicates the state of diesel particulate filter active regeneration inhibition due to the PTO being active.";
CM_ SG_ 2566749438 DslPrtcltFltrActvRgnrtnInhb_0004 "Indicates the state of diesel particulate filter active regeneration inhibition due to the service brake being active.";
CM_ SG_ 2566749438 DslPrtcltFltrActvRgnrtnInhbtdDTC "Indicates the state of diesel particulate filter active regeneration inhibition due to the clutch being disengaged.";
CM_ SG_ 2566749438 DslPrtcltFltrActvRgnrtnInhbtdDTI "Indicates the state of diesel particulate filter active regeneration inhibition due to the Diesel Particulate Filter Regeneration";
CM_ SG_ 2566749438 DslPrtcltFltrActvRgnrtnInhbtdStt "Indicates the state of diesel particulate filter active regeneration inhibition.";
CM_ SG_ 2566749438 DieselParticulateFilterStatus "Indicates the state of the diesel particulate filter regeneration need and urgency.";
CM_ SG_ 2566749438 DslPrtcltFltrActvRgnrtionStatus "Indicates the state of diesel particulate filter active regeneration.";
CM_ SG_ 2566749438 DslPrtcltFltrPssvRgnrtionStatus "Indicates the state of diesel particulate filter passive regeneration.";
CM_ SG_ 2566749438 DieselParticulateFilterLampCmd "Command to control the diesel particulate filter lamp.";
CM_ BO_ 2566831614 "Fan Drive";
CM_ SG_ 2566831614 FanSpeed "The speed of the fan associated with engine coolant system.";
CM_ SG_ 2566831614 FanDriveState "This parameter is used to indicate the current state or mode of operation by the fan drive.";
CM_ SG_ 2566831614 EstPercentFanSpeed "Estimated fan speed as a ratio of the fan drive (current speed) to the fully engaged fan drive (maximum fan speed).";
CM_ SG_ 2566831614 HydFanMotorPress "The hydraulic pressure used to drive the fan system, sensed before the hydraulic fan motor.";
CM_ SG_ 2566831614 FanDriveBypassCmdStatus "Status of the Fan Drive Bypass Command as being commanded by the ECU.";
CM_ BO_ 2566825214 "Engine Temperature 2";
CM_ SG_ 2566825214 EngExhstGsRcrculation1DiffPress "Differential pressure across the Exhaust Gas Recirculation (EGR) system";
CM_ SG_ 2566825214 EngExhaustGasRecirculation1Temp "Temperature of Recirculated Exhaust Gas.";
CM_ SG_ 2566825214 EngECUTemp "Temperature of the engine electronic control unit.";
CM_ SG_ 2566825214 EngOilTemp2 "Temperature of the engine lubricant.";
CM_ BO_ 2566844158 "Engine Temperature 1";
CM_ SG_ 2566844158 EngFuelTemp1 "Temperature of fuel (or gas) passing through the first fuel control system.";
CM_ SG_ 2566844158 EngIntercoolerThermostatOpening "The current position of the thermostat used to regulate the temperature of the engine intercooler.";
CM_ SG_ 2566844158 EngIntercoolerTemp "Temperature of liquid found in the intercooler located after the turbocharger.";
CM_ SG_ 2566844158 EngTurboOilTemp "Temperature of the turbocharger lubricant.";
CM_ SG_ 2566844158 EngOilTemp1 "Temperature of the engine lubricant.";
CM_ SG_ 2566844158 EngCoolantTemp "Temperature of liquid found in engine cooling system.";
CM_ BO_ 2566845950 "Ambient Conditions";
CM_ SG_ 2566845950 EngAirIntakeTemp "Temperature of air entering vehicle air induction system.";
CM_ SG_ 2566845950 RoadSurfaceTemp "Indicated temperature of road surface over which vehicle is operating.";
CM_ SG_ 2566845950 AmbientAirTemp "Temperature of air surrounding vehicle.";
CM_ SG_ 2566845950 CabInteriorTemp "Temperature of air inside the part of the vehicle that encloses the driver and vehicle operating controls.";
CM_ SG_ 2566845950 BarometricPress "Absolute air pressure of the atmosphere.";
CM_ BO_ 2566844414 "Engine Fluid Level/Pressure 1";
CM_ SG_ 2566844414 EngCoolantLevel "Ratio of volume of liquid found in engine cooling system to total cooling system volume.";
CM_ SG_ 2566844414 EngCoolantPress "Gage pressure of liquid found in engine cooling system.";
CM_ SG_ 2566844414 EngCrankcasePress "Gage pressure inside engine crankcase.";
CM_ SG_ 2566844414 EngOilPress "Gage pressure of oil in engine lubrication system as provided by oil pump.";
CM_ SG_ 2566844414 EngOilLevel "Ratio of current volume of engine sump oil to maximum required volume.";
CM_ SG_ 2566844414 EngExCrankcaseBlowbyPress "Differential crankcase blow-by pressure as measured through a tube with a venturi.";
CM_ SG_ 2566844414 EngFuelDeliveryPress "Gage pressure of fuel in system as delivered from supply pump to the injection pump.";
CM_ BO_ 2566846206 "Intake/Exhaust Conditions 1";
CM_ SG_ 2566846206 EngCoolantFilterDiffPress "Change in coolant pressure, measured across the filter, due to the filter and any accumulation of solid or semisolid matter";
CM_ SG_ 2566846206 EngExhaustGasTemp "Temperature of combustion byproducts leaving the engine.";
CM_ SG_ 2566846206 EngAirFilter1DiffPress "Change in engine air system pressure, measured across the filter, due to the filter and any accumulation of solid foreign";
CM_ SG_ 2566846206 EngIntakeManifold1Temp "Temperature of pre-combustion air found in intake manifold of engine air supply system.";
CM_ SG_ 2566846206 EngIntakeManifold1Press "The gage pressure measurement of the air intake manifold.";
CM_ SG_ 2566846206 EngDslPrtclateFilterIntakePress "Exhaust back pressure as a result of particle accumulation on filter media placed in the exhaust stream.";
CM_ SG_ 2566846206 EngAirIntakePress "Absolute air pressure at input port to intake manifold or air box.";
CM_ BO_ 2566763774 "Aftertreatment 1 Intake Gas 2";
CM_ SG_ 2566763774 Aftrtrtmnt1DslPrtcltFltrIntkGsTm "Used to identify the applicable J1939-73 FMI detected in the diesel particulate filter intake gas temperature sensor by the";
CM_ SG_ 2566763774 Aftrtrtmnt1ExhstGsTmp1PrlmnryFMI "Used to identify the applicable J1939-73 FMI detected in the exhaust gas temperature 1 sensor by the manufacturer's";
CM_ SG_ 2566763774 Aftertreatment1ExhaustGasTemp1 "The reading from the exhaust gas temperature sensor located farthest upstream in the aftertreatment system in exhaust bank 1.";
CM_ SG_ 2566763774 Aftrtrtmnt1DslPrtcltFltrInt_0000 "Temperature of engine combustion byproducts entering the diesel particulate filter in exhaust bank 1.";
CM_ BO_ 2566844670 "Power Takeoff Information";
CM_ SG_ 2566844670 PowerTakeoffSetSpeed "Rotational velocity selected by operator for device used to transmit engine power to auxiliary equipment.";
CM_ SG_ 2566844670 PowerTakeoffSpeed "Rotational velocity of device used to transmit engine power to auxiliary equipment.";
CM_ SG_ 2566844670 PowerTakeoffOilTemp "Temperature of lubricant in device used to transmit engine power to auxiliary equipment.";
CM_ SG_ 2566844670 OprtrEngPTOGvrnrMmrySlectSwitch "Measured state of the operator's engine PTO governor memory select switch.";
CM_ SG_ 2566844670 EngRmtPTOGvrnrVrblSpdCtrlSwitch "Switch signal which indicates that the remote PTO governor toggle switch is in the enabled (ON) position.";
CM_ SG_ 2566844670 EngRmtPTOGvrnrPrprgrmmdSpdCtrlSw "Switch signal which indicates that the remote PTO governor toggle switch is in the enabled (ON) position.";
CM_ SG_ 2566844670 EngPTOGvrnrCst_DecelerateSwitch "Switch signal of the PTO control activator which indicates that the activator is in the position to \"coast/decelerate\" the PTO";
CM_ SG_ 2566844670 EngPTOGovernorSetSwitch "Switch signal of the PTO control activator which indicates that the activator is in the position to \"set\" the engine PTO";
CM_ SG_ 2566844670 EngPTOGovernorResumeSwitch "Switch signal of the PTO control activator which indicates that the activator is in the position to \"resume\" a previously";
CM_ SG_ 2566844670 EngPTOGovernorEnableSwitch "Switch signal which indicates that the PTO governor toggle switch is in the enabled (ON) position and therefore it is";
CM_ SG_ 2566844670 EngPTOGovernorAccelerateSwitch "Switch signal of the PTO control activator which indicates that the activator is in the position to \"accelerate\" the PTO";
CM_ SG_ 2566844670 RmtPTOPrprgrmmdSpeedCtrlSwitch2 "Switch signal which indicates that the remote PTO toggle switch #2 is in the enabled (ON) position.";
CM_ SG_ 2566844670 AuxInputIgnoreSwitch "Switch signal which overrides other switch input's ability to kick out of an engine's operating condition.";
CM_ BO_ 2566845182 "Fuel Economy (Liquid)";
CM_ SG_ 2566845182 EngAverageFuelEconomy "Average of instantaneous fuel economy for that segment of vehicle operation of interest.";
CM_ SG_ 2566845182 EngInstantaneousFuelEconomy "Current fuel economy at current vehicle velocity.";
CM_ SG_ 2566845182 EngFuelRate "Amount of fuel consumed by engine per unit of time.";
CM_ SG_ 2566845182 EngThrottleValve2Pos "The sensed position feedback of the valve, coming from a second electrical actuator for a second throttle plate, used to";
CM_ SG_ 2566845182 EngThrottleValve1Pos "The position of the valve used to regulate the supply of a fluid, usually air or fuel/air mixture, to an engine.";
CM_ BO_ 2364540158 "Electronic Engine Controller 1";
CM_ SG_ 2364540158 SrcAddrssOfCtrllngDvcFrEngCntrl "The source address of the SAE J1939 device currently controlling the engine.";
CM_ SG_ 2364540158 ActlEngPrcntTrqueHighResolution "This parameter displays an additional torque in percent of the reference engine torque.";
CM_ SG_ 2364540158 EngDemandPercentTorque "The requested torque output of the engine by all dynamic internal inputs, including smoke control, noise control and low";
CM_ SG_ 2364540158 EngStarterMode "There are several phases in a starting action and different reasons why a start cannot take place.";
CM_ SG_ 2364540158 EngSpeed "Actual engine speed which is calculated over a minimum crankshaft angle of 720 degrees divided by the number of cylinders.";
CM_ SG_ 2364540158 ActualEngPercentTorque "The calculated output torque of the engine.";
CM_ SG_ 2364540158 DriversDemandEngPercentTorque "The requested torque output of the engine by the driver.";
CM_ SG_ 2364540158 EngTorqueMode "State signal which indicates which engine torque mode is currently generating, limiting, or controlling the torque.";
CM_ BO_ 2364539902 "Electronic Engine Controller 2";
CM_ SG_ 2364539902 SCRThermalManagementActive "Indicates that the exhaust temperatures have been elevated for regeneration of the SCR aftertreatment system or in";
CM_ SG_ 2364539902 MmntryEngMaxPowerEnableFeedback "Momentarily requesting Engine Maximum Power Enable - feature support feedback";
CM_ SG_ 2364539902 EstPumpingPercentTorque "The calculated torque that indicates the estimated amount of torque loss due to the engine air handling system.";
CM_ SG_ 2364539902 DPFThermalManagementActive "Indicates that the exhaust temperatures have been elevated for regeneration of the diesel particulate filter aftertreatment";
CM_ SG_ 2364539902 ActlMxAvailableEngPercentTorque "This is the maximum amount of torque that the engine can immediately deliver as a percentage of the reference engine";
CM_ SG_ 2364539902 AccelPedalPos2 "The ratio of actual position of the second analog engine speed/torque request input device (such as an accelerator pedal";
CM_ SG_ 2364539902 VhclAccelerationRateLimitStatus "Status (active or not active) of the system used to limit maximum forward vehicle acceleration.";
CM_ SG_ 2364539902 EngPercentLoadAtCurrentSpeed "The ratio of actual engine percent torque (indicated) to maximum indicated torque available at the current engine speed,";
CM_ SG_ 2364539902 AccelPedal2LowIdleSwitch "Switch signal which indicates the state of the accelerator pedal 2 low idle switch.";
CM_ SG_ 2364539902 RoadSpeedLimitStatus "Status (active or not active) of the system used to limit maximum vehicle velocity.";
CM_ SG_ 2364539902 AccelPedalKickdownSwitch "Switch signal which indicates whether the accelerator pedal kickdown switch is opened or closed.";
CM_ SG_ 2364539902 AccelPedal1LowIdleSwitch "Switch signal which indicates the state of the accelerator pedal 1 low idle switch.";
CM_ SG_ 2364539902 RemoteAccelPedalPos "The ratio of actual position of the remote analog engine speed/torque request input device (such as an accelerator pedal";
CM_ SG_ 2364539902 AccelPedalPos1 "The ratio of actual position of the analog engine speed/torque request input device (such as an accelerator pedal or";
CM_ BO_ 2566840318 "Electronic Engine Controller 3";
CM_ SG_ 2566840318 EngsDsrdOprtngSpdAsymmtryAdjstmn "This byte is utilized in transmission gear selection routines and indicates the engine's preference of lower versus higher";
CM_ SG_ 2566840318 Aftrtratment1ExhaustGasMassFlow "Measured/calculated exhaust gas mass upstream of the aftertreatment system in exhaust bank 1 and 2.";
CM_ SG_ 2566840318 Aftertreatment2IntakeDewPoint "Indicates that the temperature on the intake side of the aftertreatment system has exceeded the dew point, as estimated";
CM_ SG_ 2566840318 Aftertreatment2ExhaustDewPoint "Indicates that the temperature on the exhaust side of the aftertreatment has exceeded the dew point, as estimated by the";
CM_ SG_ 2566840318 Aftertreatment1IntakeDewPoint "Indicates that the temperature on the intake side of the aftertreatment system has exceeded the dew point, as estimated";
CM_ SG_ 2566840318 Aftertreatment1ExhaustDewPoint "Indicates that the temperature on the exhaust side of the aftertreatment has exceeded the dew point, as estimated by the";
CM_ SG_ 2566840318 EstEngPrsticLossesPercentTorque "The calculated torque that indicates the estimated amount of torque loss due to engine parasitics, such as cooling fan, air";
CM_ SG_ 2566840318 EngsDesiredOperatingSpeed "An indication by the engine of the optimal operating speed of the engine for the current existing conditions.";
CM_ SG_ 2566840318 NominalFrictionPercentTorque "The calculated torque that indicates the amount of torque required by the basic engine itself added by the loss torque of";
CM_ BO_ 2566840574 "Vehicle Distance";
CM_ SG_ 2566840574 TotalVehicleDistance "Accumulated distance traveled by vehicle during its operation.";
CM_ SG_ 2566840574 TripDistance "Distance traveled during all or part of a journey.";
CM_ BO_ 2566763518 "Aftertreatment 1 Outlet Gas 2";
CM_ SG_ 2566763518 Aftrtrtmnt1DslPrtcltFltrOtltGsTm "Temperature of engine combustion byproducts leaving the diesel particulate filter exhaust in exhaust bank 1.";
CM_ SG_ 2566763518 Aftrtrtmnt1DslPrtcltFltrOtltExhs "Used to identify the applicable J1939-73 FMI detected in the diesel particulate filter outlet gas temperature sensor by the";
CM_ SG_ 2566763518 Aftrtrtmnt1ExhstGsTmp3PrlmnryFMI "Used to identify the applicable J1939-73 FMI detected in the exhaust gas temperature 3 sensor by the manufacturer's";
CM_ SG_ 2566763518 Aftertreatment1ExhaustGasTemp3 "The reading from the exhaust gas temperature sensor located farthest downstream in the aftertreatment system in";
CM_ BO_ 2566844926 "Cruise Control/Vehicle Speed";
CM_ SG_ 2566844926 ParkBrakeReleaseInhibitRq "Park Brake Release Inhibit Request signals the desire that an applied park brake remain applied and limit the ability of the";
CM_ SG_ 2566844926 PTOGovernorState "This parameter is used to indicate the current state or mode of operation by the power takeoff (PTO) governor.";
CM_ SG_ 2566844926 EngShutdownOverrideSwitch "Switch signal which indicates the position of the engine shutdown override switch.";
CM_ SG_ 2566844926 EngTestModeSwitch "Switch signal which indicates the position of the engine test mode switch.";
CM_ SG_ 2566844926 EngIdleDecrementSwitch "Switch signal which indicates the position of the idle decrement switch.";
CM_ SG_ 2566844926 EngIdleIncrementSwitch "Switch signal which indicates the position of the idle increment switch.";
CM_ SG_ 2566844926 CruiseCtrlStates "This parameter is used to indicate the current state, or mode, of operation by the cruise control device.";
CM_ SG_ 2566844926 CruiseCtrlSetSpeed "Value of set (chosen) velocity of velocity control system.";
CM_ SG_ 2566844926 CruiseCtrlAccelerateSwitch "Switch signal of the cruise control activator which indicates that the activator is in the position [accelerate.";
CM_ SG_ 2566844926 CruiseCtrlResumeSwitch "Switch signal of the cruise control activator which indicates that the activator is in the position [resume.";
CM_ SG_ 2566844926 CruiseCtrlCoastSwitch "Switch signal of the cruise control activator which indicates that the activator is in the position [coast (decelerate).";
CM_ SG_ 2566844926 CruiseCtrlSetSwitch "Switch signal of the cruise control activator which indicates that the activator is in the position [set.";
CM_ SG_ 2566844926 ClutchSwitch "Switch signal which indicates that the clutch pedal is being pressed.";
CM_ SG_ 2566844926 BrakeSwitch "Switch signal which indicates that the driver operated brake foot pedal is being pressed.";
CM_ SG_ 2566844926 CruiseCtrlEnableSwitch "Switch signal which indicates that it is possible to manage the cruise control function.";
CM_ SG_ 2566844926 CruiseCtrlActive "Cruise control is switched on.";
CM_ SG_ 2566844926 WheelBasedVehicleSpeed "Speed of the vehicle as calculated from wheel or tailshaft speed.";
CM_ SG_ 2566844926 CruiseCtrlPauseSwitch "Switch signal which indicates the position of the Cruise Control Pause Switch used on Remote Cruise Control applications.";
CM_ SG_ 2566844926 ParkingBrakeSwitch "Switch signal which indicates when the parking brake is set.";
CM_ SG_ 2566844926 TwoSpeedAxleSwitch "Switch signal which indicates the current axle range.";
CM_ BO_ 2499624702 "Aftertreatment 1 SCR Exhaust Gas Temperature";
CM_ SG_ 2499624702 Aftrtrtmnt1SCRCtlystOtltGsTmpPrl "Used to identify the applicable J1939-73 FMI detected in the SCR catalyst outlet gas temperature sensor by the";
CM_ SG_ 2499624702 Aftrtrtmnt1SCRCtlystOtltGasTemp "Temperature of engine combustion byproducts leaving the SCR catalyst exhaust in exhaust bank 1.";
CM_ SG_ 2499624702 Aftrtrtmnt1SCRCtlystIntkGsTmpPrl "Used to identify the applicable J1939-73 FMI detected in the SCR catalyst intake gas temperature sensor by the";
CM_ SG_ 2499624702 Aftrtrtmnt1SCRCtlystIntkGasTemp "Temperature of engine combustion byproducts entering the SCR catalyst in exhaust bank 1.";
